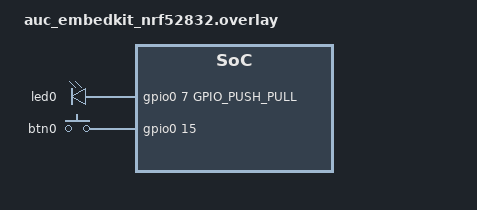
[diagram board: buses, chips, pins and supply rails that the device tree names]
// To get started, press Ctrl+Space to bring up the completion menu and view the available nodes.

// You can also use the buttons in the sidebar to perform actions on nodes.
// Actions currently available include:

// * Enabling / disabling the node
// * Adding the bus to a bus
// * Removing the node
// * Connecting ADC channels

// For more help, browse the DeviceTree documentation at https://docs.zephyrproject.org/latest/guides/dts/index.html
// You can also visit the nRF DeviceTree extension documentation at https://docs.nordicsemi.com/bundle/nrf-connect-vscode/page/guides/ncs_configure_app.html#devicetree-support-in-the-extension

&gpiote {
	status = "okay";
};

/ {
	leds {
		compatible = "gpio-leds";
        led0: led0 {
            label = "led0";
            gpios = <&gpio0 7 GPIO_PUSH_PULL>;
        };
	};
    buttons {
        compatible = "gpio-keys";
        btn0: btn0 {
            label = "btn0";
            gpios = <&gpio0 15 GPIO_PULL_UP>;
        };
    };
};
